# MIMXRT1051 register map
Vendor: nxp.com; File version: 1.0
CPU: CM7 r0p1, little endian, MPU, FPU, VTOR, 4 interrupt priority bits
Registers are 32-bit, read-write, reset 0x0 unless marked. A register's access mark holds for its fields unless they carry their own. Offsets are from the block's base; [hi:lo] are bit positions; {n}, {i} and the like mark numbered series.

## USDHC1 — uSDHC
Base 0x402C0000
Same registers: USDHC2 0x402C4000
0x00 DS_ADDR — DMA System Address
  [31:0] DS_ADDR — System address
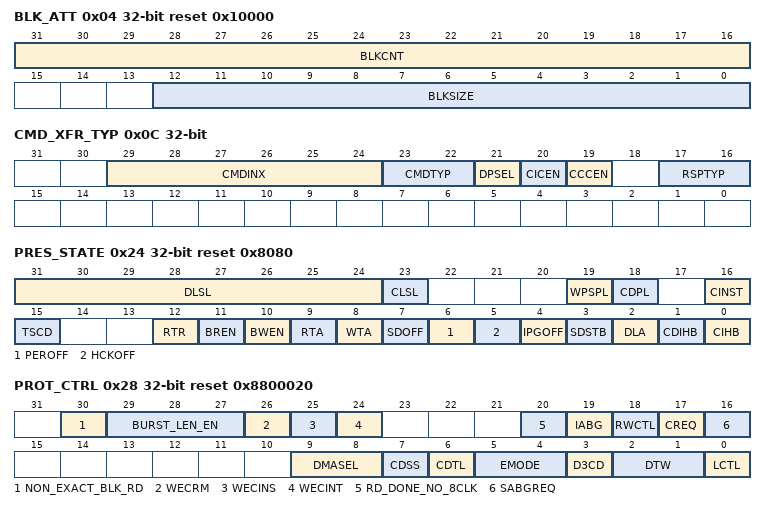
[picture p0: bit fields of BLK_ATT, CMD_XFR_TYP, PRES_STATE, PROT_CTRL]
0x04 BLK_ATT reset 0x10000 — Block Attributes
  [31:16] BLKCNT — Blocks count for current transfer
    0=Stop count; 1=1 block; 2=2 blocks; 0xFFFF=65535 blocks
  [12:0] BLKSIZE — Transfer block size
    0=No data transfer; 1=1 byte; 2=2 bytes; 3=3 bytes; 4=4 bytes; 0x1FF=511 bytes; 0x200=512 bytes; 0x800=2048 bytes; 0x1000=4096 bytes
0x08 CMD_ARG — Command Argument
  [31:0] CMDARG — Command argument
0x0C CMD_XFR_TYP — Command Transfer Type
  [29:24] CMDINX — Command index
  [23:22] CMDTYP — Command type
    0=Normal other commands; 1=Suspend CMD52 for writing bus suspend in CCCR; 2=Resume CMD52 for writing function select in CCCR; 3=Abort CMD12, CMD52 for writing I/O Abort in CCCR
  [21] DPSEL — Data present select
    0=No data present; 1=Data present
  [20] CICEN — Command index check enable
    0=Disable command index check; 1=Enables command index check
  [19] CCCEN — Command CRC check enable
    0=Disables command CRC check; 1=Enables command CRC check
  [17:16] RSPTYP — Response type select
    0=No response; 1=Response length 136; 2=Response length 48; 3=Response length 48, check busy after response
{0x10+4i} CMD_RSP{i} ro (i=0..3) — Command Response{i}
  [31:0] CMDRSP{i} — Command response {i}
0x20 DATA_BUFF_ACC_PORT — Data Buffer Access Port
  [31:0] DATCONT — Data content
0x24 PRES_STATE ro reset 0x8080 (reset mask 0x72FFFF) — Present State
  [31:24] DLSL — DATA[7:0] line signal level
    {v}=DATA{v} (Data {v} line signal level) (v=0..7)
  [23] CLSL — CMD line signal level
  [19] WPSPL — Write protect switch pin level
    0=Write protected (WP = 1); 1=Write enabled (WP = 0)
  [18] CDPL — Card detect pin level
    0=No card present (CD_B = 1); 1=Card present (CD_B = 0)
  [16] CINST — Card inserted
    0=Power on reset or no card; 1=Card inserted
  [15] TSCD — Tape select change done
    0=Delay cell select change is not finished; 1=Delay cell select change is finished
  [12] RTR — Re-Tuning Request (only for SD3.0 SDR104 mode and EMMC HS200 mode)
    0=Fixed or well tuned sampling clock; 1=Sampling clock needs re-tuning
  [11] BREN — Buffer read enable
    0=Read disable; 1=Read enable
  [10] BWEN — Buffer write enable
    0=Write disable; 1=Write enable
  [9] RTA — Read transfer active
    0=No valid data; 1=Transferring data
  [8] WTA — Write transfer active
    0=No valid data; 1=Transferring data
  [7] SDOFF — SD clock gated off internally
    0=SD clock is active; 1=SD clock is gated off
  [6] PEROFF — IPG_PERCLK gated off internally
    0=IPG_PERCLK is active; 1=IPG_PERCLK is gated off
  [5] HCKOFF — HCLK gated off internally
    0=HCLK is active; 1=HCLK is gated off
  [4] IPGOFF — Peripheral clock gated off internally
    0=Peripheral clock is active; 1=Peripheral clock is gated off
  [3] SDSTB — SD clock stable
    0=Clock is changing frequency and not stable; 1=Clock is stable
  [2] DLA — Data line active
    0=DATA line inactive; 1=DATA line active
  [1] CDIHB — Command inhibit (DATA)
    0=Can issue command that uses the DATA line; 1=Cannot issue command that uses the DATA line
  [0] CIHB — Command inhibit (CMD)
    0=Can issue command using only CMD line; 1=Cannot issue command
0x28 PROT_CTRL reset 0x8800020 — Protocol Control
  [30] NON_EXACT_BLK_RD — Non-exact block read
    0=The block read is exact block read. Host driver does not need to issue abort command to terminate this multi-block read.; 1=The block read is non-exact block read. Host driver needs to issue abort command to terminate this multi-block read.
  [29:27] BURST_LEN_EN — BURST length enable for INCR, INCR4 / INCR8 / INCR16, INCR4-WRAP / INCR8-WRAP / INCR16-WRAP
    0bxx1=Burst length is enabled for INCR
  [26] WECRM — Wakeup event enable on SD card removal
    0=Disables wakeup event enable on SD card removal; 1=Enables wakeup event enable on SD card removal
  [25] WECINS — Wakeup event enable on SD card insertion
    0=Disable wakeup event enable on SD card insertion; 1=Enable wakeup event enable on SD card insertion
  [24] WECINT — Wakeup event enable on card interrupt
    0=Disables wakeup event enable on card interrupt; 1=Enables wakeup event enable on card interrupt
  [20] RD_DONE_NO_8CLK — Read performed number 8 clock
  [19] IABG — Interrupt at block gap
    0=Disables interrupt at block gap; 1=Enables interrupt at block gap
  [18] RWCTL — Read wait control
    0=Disables read wait control and stop SD clock at block gap when SABGREQ field is set; 1=Enables read wait control and assert read wait without stopping SD clock at block gap when SABGREQ field is set
  [17] CREQ — Continue request
    0=No effect; 1=Restart
  [16] SABGREQ — Stop at block gap request
    0=Transfer; 1=Stop
  [9:8] DMASEL — DMA select
    0=No DMA or simple DMA is selected; 1=ADMA1 is selected; 2=ADMA2 is selected
  [7] CDSS — Card detect signal selection
    0=Card detection level is selected (for normal purpose); 1=Card detection test level is selected (for test purpose)
  [6] CDTL — Card detect test level
    0=Card detect test level is 0, no card inserted; 1=Card detect test level is 1, card inserted
  [5:4] EMODE — Endian mode
    0=Big endian mode; 1=Half word big endian mode; 2=Little endian mode
  [3] D3CD — DATA3 as card detection pin
    0=DATA3 does not monitor card insertion; 1=DATA3 as card detection pin
  [2:1] DTW — Data transfer width
    0=1-bit mode; 1=4-bit mode; 2=8-bit mode
  [0] LCTL — LED control
    0=LED off; 1=LED on
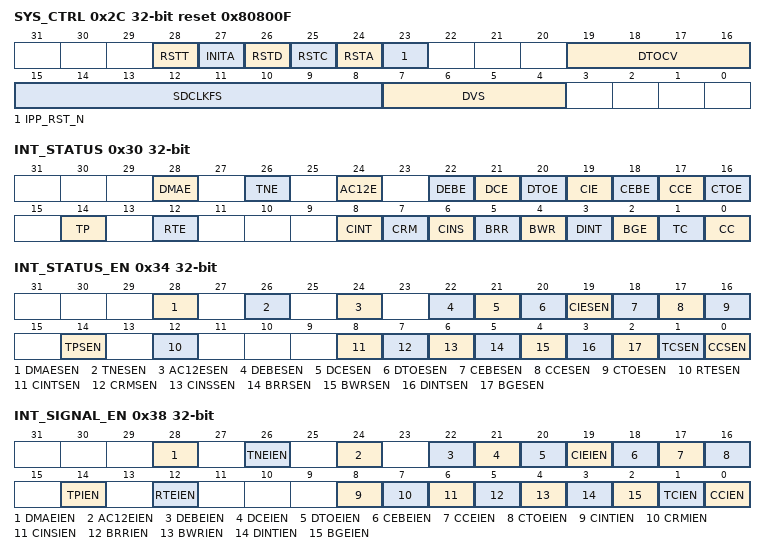
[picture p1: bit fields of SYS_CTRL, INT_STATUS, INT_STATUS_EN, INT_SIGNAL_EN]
0x2C SYS_CTRL reset 0x80800F — System Control
  [28] RSTT — Reset tuning
  [27] INITA — Initialization active
  [26] RSTD — Software reset for data line
    0=No reset; 1=Reset
  [25] RSTC — Software reset for CMD line
    0=No reset; 1=Reset
  [24] RSTA — Software reset for all
    0=No reset; 1=Reset
  [23] IPP_RST_N — Hardware reset
  [19:16] DTOCV — Data timeout counter value
    0=SDCLK x 2 32; 1=SDCLK x 2 33; 2=SDCLK x 2 18; 3=SDCLK x 2 19; 13=SDCLK x 2 29 recommend to use for other speed mode except HS400/HS200/SDR104 mode; 14=SDCLK x 2 30 recommend to use for HS200/SDR104 mode; 15=SDCLK x 2 31 recommend to use for HS400 mode
  [15:8] SDCLKFS — SDCLK frequency select
  [7:4] DVS — Divisor
    0=Divide-by-1; 1=Divide-by-2; 14=Divide-by-15; 15=Divide-by-16
0x30 INT_STATUS — Interrupt Status
  [28] DMAE write-1-clears — DMA error
    0=No error; 1=Error
  [26] TNE write-1-clears — Tuning error: (only for SD3.0 SDR104 mode and EMMC HS200 mode)
  [24] AC12E write-1-clears — Auto CMD12 error
    0=No error; 1=Error
  [22] DEBE write-1-clears — Data end bit error
    0=No error; 1=Error
  [21] DCE write-1-clears — Data CRC error
    0=No error; 1=Error
  [20] DTOE write-1-clears — Data timeout error
    0=No error; 1=Time out
  [19] CIE write-1-clears — Command index error
    0=No error; 1=Error
  [18] CEBE write-1-clears — Command end bit error
    0=No error; 1=End bit error generated
  [17] CCE write-1-clears — Command CRC error
    0=No error; 1=CRC error generated
  [16] CTOE write-1-clears — Command timeout error
    0=No error; 1=Time out
  [14] TP write-1-clears — Tuning pass:(only for SD3.0 SDR104 mode and EMMC HS200 mode)
  [12] RTE write-1-clears — Re-tuning event: (only for SD3.0 SDR104 mode and EMMC HS200 mode)
    0=Re-tuning is not required; 1=Re-tuning should be performed
  [8] CINT write-1-clears — Card interrupt
    0=No card interrupt; 1=Generate card interrupt
  [7] CRM write-1-clears — Card removal
    0=Card state unstable or inserted; 1=Card removed
  [6] CINS write-1-clears — Card insertion
    0=Card state unstable or removed; 1=Card inserted
  [5] BRR write-1-clears — Buffer read ready
    0=Not ready to read buffer; 1=Ready to read buffer
  [4] BWR write-1-clears — Buffer write ready
    0=Not ready to write buffer; 1=Ready to write buffer
  [3] DINT write-1-clears — DMA interrupt
    0=No DMA interrupt; 1=DMA interrupt is generated
  [2] BGE write-1-clears — Block gap event
    0=No block gap event; 1=Transaction stopped at block gap
  [1] TC write-1-clears — Transfer complete
    0=Transfer does not complete; 1=Transfer complete
  [0] CC write-1-clears — Command complete
    0=Command not complete; 1=Command complete
0x34 INT_STATUS_EN — Interrupt Status Enable
  [all] fields
    0=Masked; 1=Enabled
  [28] DMAESEN — DMA error status enable
  [26] TNESEN — Tuning error status enable
  [24] AC12ESEN — Auto CMD12 error status enable
  [22] DEBESEN — Data end bit error status enable
  [21] DCESEN — Data CRC error status enable
  [20] DTOESEN — Data timeout error status enable
  [19] CIESEN — Command index error status enable
  [18] CEBESEN — Command end bit error status enable
  [17] CCESEN — Command CRC error status enable
  [16] CTOESEN — Command timeout error status enable
  [14] TPSEN — Tuning pass status enable
  [12] RTESEN — Re-tuning event status enable
  [8] CINTSEN — Card interrupt status enable
  [7] CRMSEN — Card removal status enable
  [6] CINSSEN — Card insertion status enable
  [5] BRRSEN — Buffer read ready status enable
  [4] BWRSEN — Buffer write ready status enable
  [3] DINTSEN — DMA interrupt status enable
  [2] BGESEN — Block gap event status enable
  [1] TCSEN — Transfer complete status enable
  [0] CCSEN — Command complete status enable
0x38 INT_SIGNAL_EN — Interrupt Signal Enable
  [28] DMAEIEN — DMA error interrupt enable
    0=Masked; 1=Enable
  [26] TNEIEN — Tuning error interrupt enable
    0=Masked; 1=Enabled
  [24] AC12EIEN — Auto CMD12 error interrupt enable
    0=Masked; 1=Enabled
  [22] DEBEIEN — Data end bit error interrupt enable
    0=Masked; 1=Enabled
  [21] DCEIEN — Data CRC error interrupt enable
    0=Masked; 1=Enabled
  [20] DTOEIEN — Data timeout error interrupt enable
    0=Masked; 1=Enabled
  [19] CIEIEN — Command index error interrupt enable
    0=Masked; 1=Enabled
  [18] CEBEIEN — Command end bit error interrupt enable
    0=Masked; 1=Enabled
  [17] CCEIEN — Command CRC error interrupt enable
    0=Masked; 1=Enabled
  [16] CTOEIEN — Command timeout error interrupt enable
    0=Masked; 1=Enabled
  [14] TPIEN — Tuning Pass interrupt enable
    0=Masked; 1=Enabled
  [12] RTEIEN — Re-tuning event interrupt enable
    0=Masked; 1=Enabled
  [8] CINTIEN — Card interrupt enable
    0=Masked; 1=Enabled
  [7] CRMIEN — Card removal interrupt enable
    0=Masked; 1=Enabled
  [6] CINSIEN — Card insertion interrupt enable
    0=Masked; 1=Enabled
  [5] BRRIEN — Buffer read ready interrupt enable
    0=Masked; 1=Enabled
  [4] BWRIEN — Buffer write ready interrupt enable
    0=Masked; 1=Enabled
  [3] DINTIEN — DMA interrupt enable
    0=Masked; 1=Enabled
  [2] BGEIEN — Block gap event interrupt enable
    0=Masked; 1=Enabled
  [1] TCIEN — Transfer complete interrupt enable
    0=Masked; 1=Enabled
  [0] CCIEN — Command complete interrupt enable
    0=Masked; 1=Enabled
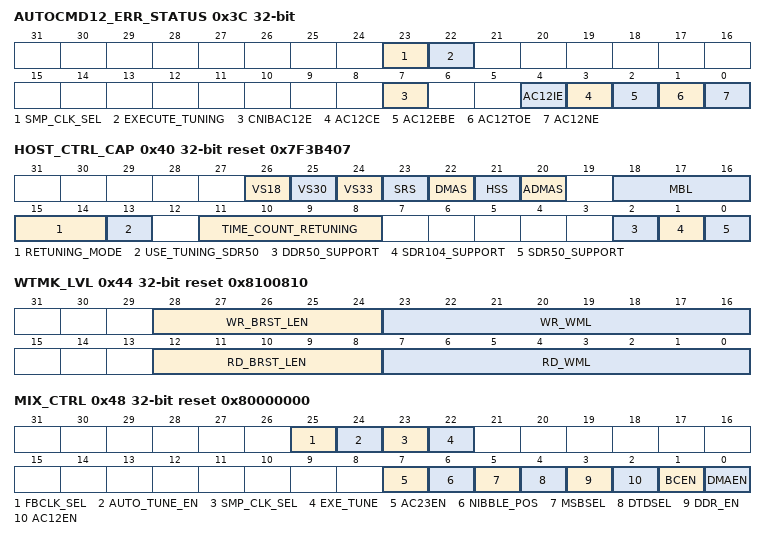
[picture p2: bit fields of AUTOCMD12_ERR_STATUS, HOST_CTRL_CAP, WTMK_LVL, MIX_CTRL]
0x3C AUTOCMD12_ERR_STATUS — Auto CMD12 Error Status
  [23] SMP_CLK_SEL — Sample clock select
    0=Fixed clock is used to sample data; 1=Tuned clock is used to sample data
  [22] EXECUTE_TUNING
  [7] CNIBAC12E ro — Command not issued by Auto CMD12 error
    0=No error; 1=Not issued
  [4] AC12IE ro — Auto CMD12 / 23 index error
    0=No error; 1=Error, the CMD index in response is not CMD12/23
  [3] AC12CE ro — Auto CMD12 / 23 CRC error
    0=No CRC error; 1=CRC error met in Auto CMD12/23 response
  [2] AC12EBE ro — Auto CMD12 / 23 end bit error
    0=No error; 1=End bit error generated
  [1] AC12TOE ro — Auto CMD12 / 23 timeout error
    0=No error; 1=Time out
  [0] AC12NE ro — Auto CMD12 not executed
    0=Executed; 1=Not executed
0x40 HOST_CTRL_CAP reset 0x7F3B407 — Host Controller Capabilities
  [26] VS18 ro — Voltage support 1.8 V
    0=1.8 V not supported; 1=1.8 V supported
  [25] VS30 ro — Voltage support 3.0 V
    0=3.0 V not supported; 1=3.0 V supported
  [24] VS33 ro — Voltage support 3.3 V
    0=3.3 V not supported; 1=3.3 V supported
  [23] SRS ro — Suspend / resume support
    0=Not supported; 1=Supported
  [22] DMAS ro — DMA support
    0=DMA not supported; 1=DMA supported
  [21] HSS ro — High speed support
    0=High speed not supported; 1=High speed supported
  [20] ADMAS ro — ADMA support
    0=Advanced DMA not supported; 1=Advanced DMA supported
  [18:16] MBL ro — Max block length
    0=512 bytes; 1=1024 bytes; 2=2048 bytes; 3=4096 bytes
  [15:14] RETUNING_MODE ro
    0=Mode 1; 1=Mode 2; 2=Mode 3
  [13] USE_TUNING_SDR50 — Use Tuning for SDR50
    0=SDR does not require tuning; 1=SDR50 requires tuning
  [11:8] TIME_COUNT_RETUNING — Time counter for retuning
  [2] DDR50_SUPPORT ro
  [1] SDR104_SUPPORT ro
  [0] SDR50_SUPPORT ro
0x44 WTMK_LVL reset 0x8100810 — Watermark Level
  [28:24] WR_BRST_LEN — Write burst length due to system restriction, the actual burst length might not exceed 16
  [23:16] WR_WML — Write watermark level
  [12:8] RD_BRST_LEN — Read burst length due to system restriction, the actual burst length might not exceed 16
  [7:0] RD_WML — Read watermark level
0x48 MIX_CTRL reset 0x80000000 — Mixer Control
  [25] FBCLK_SEL — Feedback clock source selection (Only used for SD3.0, SDR104 mode and EMMC HS200 mode)
    0=Feedback clock comes from the loopback CLK; 1=Feedback clock comes from the ipp_card_clk_out
  [24] AUTO_TUNE_EN — Auto tuning enable (Only used for SD3.0, SDR104 mode and and EMMC HS200 mode)
    0=Disable auto tuning; 1=Enable auto tuning
  [23] SMP_CLK_SEL — Clock selection
    0=Fixed clock is used to sample data / cmd; 1=Tuned clock is used to sample data / cmd
  [22] EXE_TUNE — Execute tuning: (Only used for SD3.0, SDR104 mode and EMMC HS200 mode)
    0=Not tuned or tuning completed; 1=Execute tuning
  [7] AC23EN — Auto CMD23 enable
  [6] NIBBLE_POS — Nibble position indication
  [5] MSBSEL — Multi / Single block select
    0=Single block; 1=Multiple blocks
  [4] DTDSEL — Data transfer direction select
    0=Write (Host to card); 1=Read (Card to host)
  [3] DDR_EN — Dual data rate mode selection
  [2] AC12EN — Auto CMD12 enable
    0=Disable; 1=Enable
  [1] BCEN — Block count enable
    0=Disable; 1=Enable
  [0] DMAEN — DMA enable
    0=Disable; 1=Enable
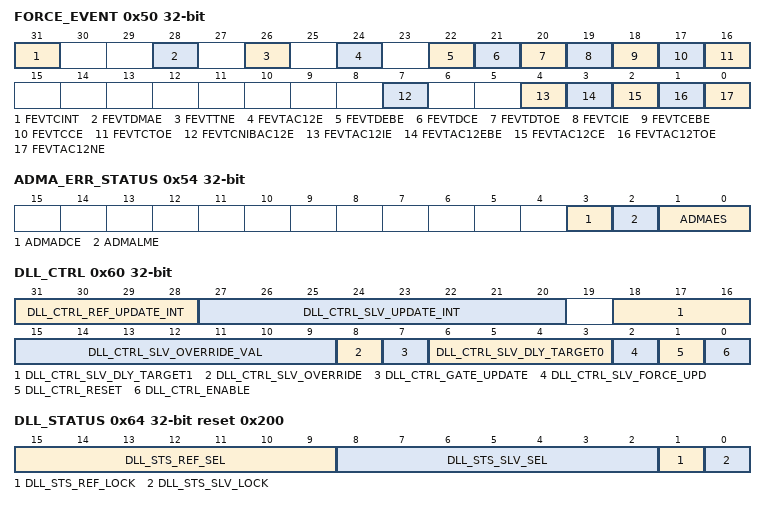
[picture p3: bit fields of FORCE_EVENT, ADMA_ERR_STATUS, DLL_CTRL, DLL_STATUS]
0x50 FORCE_EVENT
  [31] FEVTCINT — Force event card interrupt
  [28] FEVTDMAE — Force event DMA error
  [26] FEVTTNE — Force tuning error
  [24] FEVTAC12E — Force event Auto Command 12 error
  [22] FEVTDEBE — Force event data end bit error
  [21] FEVTDCE — Force event data CRC error
  [20] FEVTDTOE — Force event data time out error
  [19] FEVTCIE — Force event command index error
  [18] FEVTCEBE — Force event command end bit error
  [17] FEVTCCE — Force event command CRC error
  [16] FEVTCTOE — Force event command time out error
  [7] FEVTCNIBAC12E — Force event command not executed by Auto Command 12 error
  [4] FEVTAC12IE — Force event Auto Command 12 index error
  [3] FEVTAC12EBE — Force event Auto Command 12 end bit error
  [2] FEVTAC12CE — Force event auto command 12 CRC error
  [1] FEVTAC12TOE — Force event auto command 12 time out error
  [0] FEVTAC12NE — Force event auto command 12 not executed
0x54 ADMA_ERR_STATUS ro — ADMA Error Status
  [3] ADMADCE — ADMA descriptor error
    0=No error; 1=Error
  [2] ADMALME — ADMA length mismatch error
    0=No error; 1=Error
  [1:0] ADMAES — ADMA error state (when ADMA error is occurred)
0x58 ADMA_SYS_ADDR — ADMA System Address
  [31:2] ADS_ADDR — ADMA system address
0x60 DLL_CTRL — DLL (Delay Line) Control
  [31:28] DLL_CTRL_REF_UPDATE_INT — DLL control loop update interval
  [27:20] DLL_CTRL_SLV_UPDATE_INT — Slave delay line update interval
  [18:16] DLL_CTRL_SLV_DLY_TARGET1 — DLL slave delay target1
  [15:9] DLL_CTRL_SLV_OVERRIDE_VAL — DLL slave override val
  [8] DLL_CTRL_SLV_OVERRIDE — DLL slave override
  [7] DLL_CTRL_GATE_UPDATE — DLL gate update
  [6:3] DLL_CTRL_SLV_DLY_TARGET0 — DLL slave delay target0
  [2] DLL_CTRL_SLV_FORCE_UPD — DLL slave delay line
  [1] DLL_CTRL_RESET — DLL reset
  [0] DLL_CTRL_ENABLE — DLL and delay chain
0x64 DLL_STATUS ro reset 0x200
  [15:9] DLL_STS_REF_SEL — Reference delay line select taps
  [8:2] DLL_STS_SLV_SEL — Slave delay line select status
  [1] DLL_STS_REF_LOCK — Reference DLL lock status
  [0] DLL_STS_SLV_LOCK — Slave delay-line lock status
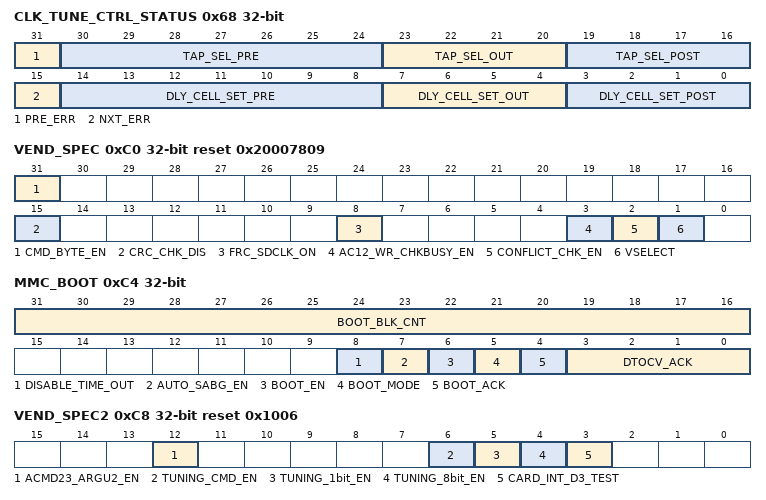
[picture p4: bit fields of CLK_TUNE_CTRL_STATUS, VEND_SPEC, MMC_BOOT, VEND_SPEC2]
0x68 CLK_TUNE_CTRL_STATUS — CLK Tuning Control and Status
  [31] PRE_ERR ro — PRE error
  [30:24] TAP_SEL_PRE ro
  [23:20] TAP_SEL_OUT ro — Delay cells added on the feedback clock between CLK_PRE and CLK_OUT
  [19:16] TAP_SEL_POST ro — Delay cells added on the feedback clock between CLK_OUT and CLK_POST
  [15] NXT_ERR ro — NXT error
  [14:8] DLY_CELL_SET_PRE — delay cells on the feedback clock between the feedback clock and CLK_PRE
  [7:4] DLY_CELL_SET_OUT — Delay cells on the feedback clock between CLK_PRE and CLK_OUT
  [3:0] DLY_CELL_SET_POST — Delay cells on the feedback clock between CLK_OUT and CLK_POST
0xC0 VEND_SPEC reset 0x20007809 — Vendor Specific Register
  [31] CMD_BYTE_EN — Byte access
    0=Disable; 1=Enable
  [15] CRC_CHK_DIS — CRC Check Disable
    0=Check CRC16 for every read data packet and check CRC fields for every write data packet; 1=Ignore CRC16 check for every read data packet and ignore CRC fields check for every write data packet
  [8] FRC_SDCLK_ON — Force CLK
    0=CLK active or inactive is fully controlled by the hardware; 1=Force CLK active
  [3] AC12_WR_CHKBUSY_EN — Check busy enable
    0=Do not check busy after auto CMD12 for write data packet; 1=Check busy after auto CMD12 for write data packet
  [2] CONFLICT_CHK_EN — Conflict check enable
    0=Conflict check disable; 1=Conflict check enable
  [1] VSELECT — Voltage selection
    0=Change the voltage to high voltage range, around 3.0 V; 1=Change the voltage to low voltage range, around 1.8 V
0xC4 MMC_BOOT
  [31:16] BOOT_BLK_CNT — Stop At Block Gap value of automatic mode
  [8] DISABLE_TIME_OUT — Time out
    0=Enable time out; 1=Disable time out
  [7] AUTO_SABG_EN — Auto stop at block gap
  [6] BOOT_EN — Boot enable
    0=Fast boot disable; 1=Fast boot enable
  [5] BOOT_MODE
    0=Normal boot; 1=Alternative boot
  [4] BOOT_ACK
    0=No ack; 1=Ack
  [3:0] DTOCV_ACK — Boot ACK time out
    {v}=SDCLK x 2^{v+14} (v=0..7); 14=SDCLK x 2^28; 15=SDCLK x 2^29
0xC8 VEND_SPEC2 reset 0x1006 — Vendor Specific 2 Register
  [12] ACMD23_ARGU2_EN — Argument2 register enable for ACMD23
    0=Disable; 1=Argument2 register enable for ACMD23 sharing with SDMA system address register. Default is enabled.
  [6] TUNING_CMD_EN — Tuning command enable
    0=Auto tuning circuit does not check the CMD line; 1=Auto tuning circuit checks the CMD line
  [5] TUNING_1bit_EN — Tuning 1bit enable
  [4] TUNING_8bit_EN — Tuning 8bit enable
  [3] CARD_INT_D3_TEST — Card interrupt detection test
    0=Check the card interrupt only when DATA3 is high; 1=Check the card interrupt by ignoring the status of DATA3
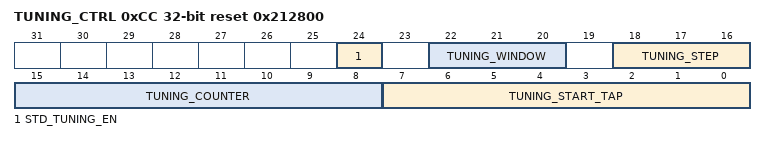
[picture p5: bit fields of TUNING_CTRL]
0xCC TUNING_CTRL reset 0x212800 — Tuning Control
  [24] STD_TUNING_EN — Standard tuning circuit and procedure enable
  [22:20] TUNING_WINDOW — Data window
  [18:16] TUNING_STEP
  [15:8] TUNING_COUNTER
  [7:0] TUNING_START_TAP — Tuning start
